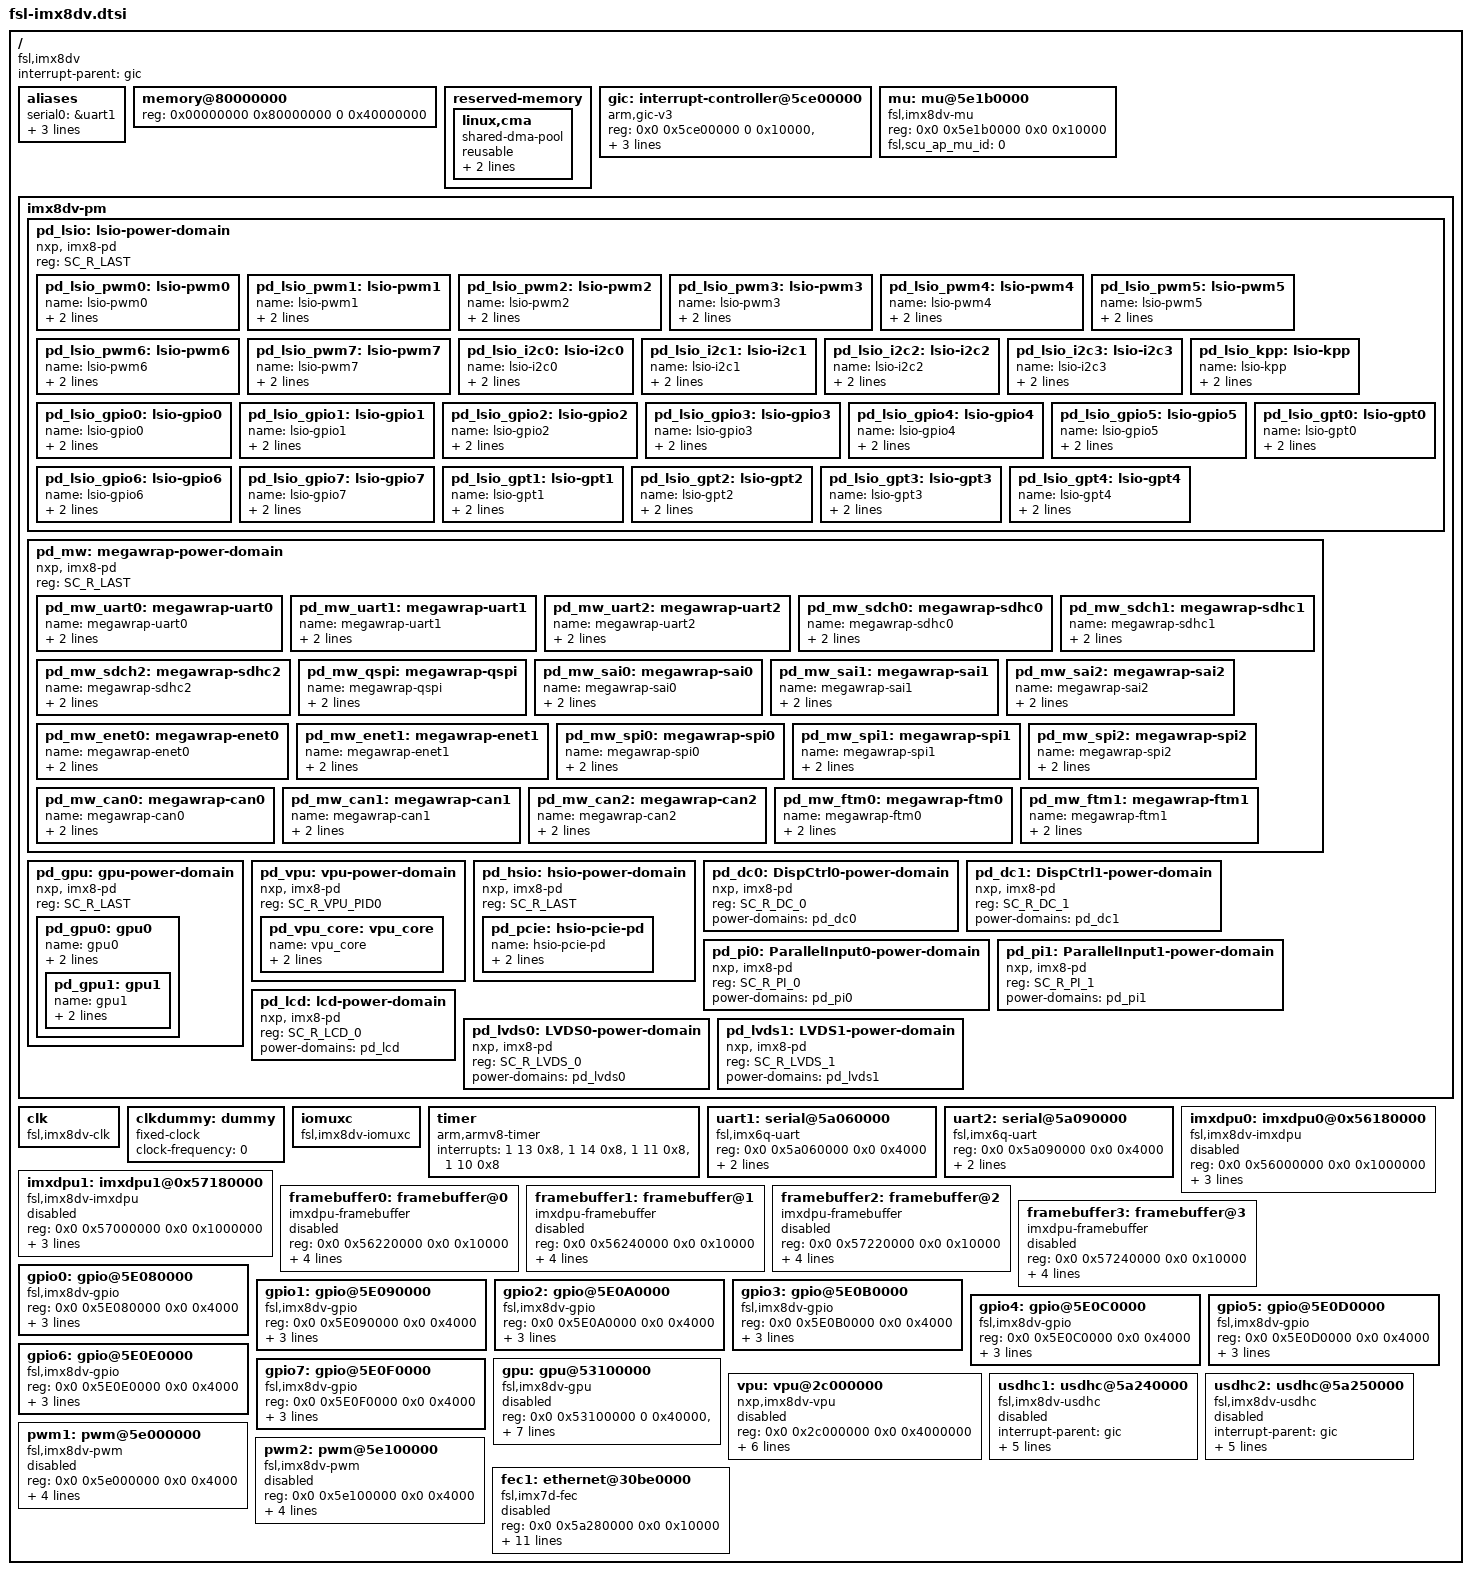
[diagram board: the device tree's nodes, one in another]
/*
 * Device Tree Include file for Freescale i.MX8 family SoC.
 *
 * Copyright (C) 2015, Freescale Semiconductor inc
 *
 * Nitin Garg <nitin.garg@freescale.com>
 *
 * This file is dual-licensed: you can use it either under the terms
 * of the GPLv2 or the X11 license, at your option. Note that this dual
 * licensing only applies to this file, and not this project as a
 * whole.
 *
 *  a) This library is free software; you can redistribute it and/or
 *     modify it under the terms of the GNU General Public License as
 *     published by the Free Software Foundation; either version 2 of the
 *     License, or (at your option) any later version.
 *
 *     This library is distributed in the hope that it will be useful,
 *     but WITHOUT ANY WARRANTY; without even the implied warranty of
 *     MERCHANTABILITY or FITNESS FOR A PARTICULAR PURPOSE.  See the
 *     GNU General Public License for more details.
 *
 *     You should have received a copy of the GNU General Public
 *     License along with this library; if not, write to the Free
 *     Software Foundation, Inc., 51 Franklin St, Fifth Floor, Boston,
 *     MA 02110-1301 USA
 *
 * Or, alternatively,
 *
 *  b) Permission is hereby granted, free of charge, to any person
 *     obtaining a copy of this software and associated documentation
 *     files (the "Software"), to deal in the Software without
 *     restriction, including without limitation the rights to use,
 *     copy, modify, merge, publish, distribute, sublicense, and/or
 *     sell copies of the Software, and to permit persons to whom the
 *     Software is furnished to do so, subject to the following
 *     conditions:
 *
 *     The above copyright notice and this permission notice shall be
 *     included in all copies or substantial portions of the Software.
 *
 *     THE SOFTWARE IS PROVIDED "AS IS", WITHOUT WARRANTY OF ANY KIND,
 *     EXPRESS OR IMPLIED, INCLUDING BUT NOT LIMITED TO THE WARRANTIES
 *     OF MERCHANTABILITY, FITNESS FOR A PARTICULAR PURPOSE AND
 *     NONINFRINGEMENT. IN NO EVENT SHALL THE AUTHORS OR COPYRIGHT
 *     HOLDERS BE LIABLE FOR ANY CLAIM, DAMAGES OR OTHER LIABILITY,
 *     WHETHER IN AN ACTION OF CONTRACT, TORT OR OTHERWISE, ARISING
 *     FROM, OUT OF OR IN CONNECTION WITH THE SOFTWARE OR THE USE OR
 *     OTHER DEALINGS IN THE SOFTWARE.
 */

#include "fsl-imx8dv-ca53.dtsi"
#include <dt-bindings/clock/imx8dv-clock.h>
#include <dt-bindings/soc/imx_rsrc.h>

/ {
	compatible = "fsl,imx8dv";
	interrupt-parent = <&gic>;
	#address-cells = <2>;
	#size-cells = <2>;

	aliases {
		serial0 = &uart1;
		serial1 = &uart2;
		mmc0 = &usdhc1;
        ethernet0 = &fec1;
	};

	memory@80000000 {
		device_type = "memory";
		reg = <0x00000000 0x80000000 0 0x40000000>;
		      /* DRAM space - 1, size : 1 GB DRAM */
	};

        reserved-memory {
		#address-cells = <2>;
                #size-cells = <2>;
                ranges;

                /* global autoconfigured region for contiguous allocations */
                linux,cma {
                        compatible = "shared-dma-pool";
                        reusable;
                        size = <0 0x08000000>;
                        linux,cma-default;
                };
        };

	gic: interrupt-controller@5ce00000 {
		compatible = "arm,gic-v3";
		reg = <0x0 0x5ce00000 0 0x10000>, /* GIC Dist */
		      <0x0 0x5cf00000 0 0xC0000>; /* GICR (RD_base + SGI_base) */
		#interrupt-cells = <3>;
		interrupt-controller;
		interrupts = <1 9 0x4>;
	};

	mu: mu@5e1b0000 {
		compatible = "fsl,imx8dv-mu","fsl,imx7d-mu", "fsl,imx6sx-mu";
		reg = <0x0 0x5e1b0000 0x0 0x10000>;
		fsl,scu_ap_mu_id = <0>;
		status = "okay";
	};

	imx8dv-pm {
		#address-cells = <1>;
		#size-cells = <0>;

		pd_lsio: lsio-power-domain {
			compatible = "nxp, imx8-pd";
			reg = <SC_R_LAST>;
			#power-domain-cells = <0>;
			#address-cells = <1>;
			#size-cells = <0>;
			pd_lsio_pwm0: lsio-pwm0 {
				name = "lsio-pwm0";
				reg = <SC_R_PWM_0>;
				#power-domain-cells = <0>;
				power-domains = <&pd_lsio>;
			};
			pd_lsio_pwm1: lsio-pwm1 {
				name = "lsio-pwm1";
				reg = <SC_R_PWM_1>;
				#power-domain-cells = <0>;
				power-domains = <&pd_lsio>;
			};
			pd_lsio_pwm2: lsio-pwm2 {
				name = "lsio-pwm2";
				reg = <SC_R_PWM_2>;
				#power-domain-cells = <0>;
				power-domains = <&pd_lsio>;
			};
			pd_lsio_pwm3: lsio-pwm3 {
				name = "lsio-pwm3";
				reg = <SC_R_PWM_3>;
				#power-domain-cells = <0>;
				power-domains = <&pd_lsio>;
			};
			pd_lsio_pwm4: lsio-pwm4 {
				name = "lsio-pwm4";
				reg = <SC_R_PWM_4>;
				#power-domain-cells = <0>;
				power-domains = <&pd_lsio>;
			};
			pd_lsio_pwm5: lsio-pwm5 {
				name = "lsio-pwm5";
				reg = <SC_R_PWM_5>;
				#power-domain-cells = <0>;
				power-domains = <&pd_lsio>;
			};
			pd_lsio_pwm6: lsio-pwm6 {
				name = "lsio-pwm6";
				reg = <SC_R_PWM_6>;
				#power-domain-cells = <0>;
				power-domains = <&pd_lsio>;
			};
			pd_lsio_pwm7: lsio-pwm7 {
				name = "lsio-pwm7";
				reg = <SC_R_PWM_7>;
				#power-domain-cells = <0>;
				power-domains = <&pd_lsio>;
			};
			pd_lsio_i2c0: lsio-i2c0 {
				name = "lsio-i2c0";
				reg = <SC_R_I2C_0>;
				#power-domain-cells = <0>;
				power-domains = <&pd_lsio>;
			};
			pd_lsio_i2c1: lsio-i2c1 {
				name = "lsio-i2c1";
				reg = <SC_R_I2C_1>;
				#power-domain-cells = <0>;
				power-domains = <&pd_lsio>;
			};
			pd_lsio_i2c2: lsio-i2c2 {
				name = "lsio-i2c2";
				reg = <SC_R_I2C_2>;
				#power-domain-cells = <0>;
				power-domains = <&pd_lsio>;
			};
			pd_lsio_i2c3: lsio-i2c3 {
				name = "lsio-i2c3";
				reg = <SC_R_I2C_3>;
				#power-domain-cells = <0>;
				power-domains = <&pd_lsio>;
			};
			pd_lsio_kpp: lsio-kpp {
				name = "lsio-kpp";
				reg = <SC_R_KPP>;
				#power-domain-cells = <0>;
				power-domains = <&pd_lsio>;
			};
			pd_lsio_gpio0: lsio-gpio0 {
				name = "lsio-gpio0";
				reg = <SC_R_GPIO_0>;
				#power-domain-cells = <0>;
				power-domains = <&pd_lsio>;
			};
			pd_lsio_gpio1: lsio-gpio1 {
				name = "lsio-gpio1";
				reg = <SC_R_GPIO_1>;
				#power-domain-cells = <0>;
				power-domains = <&pd_lsio>;
			};
			pd_lsio_gpio2: lsio-gpio2 {
				name = "lsio-gpio2";
				reg = <SC_R_GPIO_2>;
				#power-domain-cells = <0>;
				power-domains = <&pd_lsio>;
			};
			pd_lsio_gpio3: lsio-gpio3 {
				name = "lsio-gpio3";
				reg = <SC_R_GPIO_3>;
				#power-domain-cells = <0>;
				power-domains = <&pd_lsio>;
			};
			pd_lsio_gpio4: lsio-gpio4 {
				name = "lsio-gpio4";
				reg = <SC_R_GPIO_4>;
				#power-domain-cells = <0>;
				power-domains = <&pd_lsio>;
			};
			pd_lsio_gpio5: lsio-gpio5 {
				name = "lsio-gpio5";
				reg = <SC_R_GPIO_5>;
				#power-domain-cells = <0>;
				power-domains = <&pd_lsio>;
			};
			pd_lsio_gpio6: lsio-gpio6 {
				name = "lsio-gpio6";
				reg = <SC_R_GPIO_6>;
				#power-domain-cells = <0>;
				power-domains = <&pd_lsio>;
			};
			pd_lsio_gpio7: lsio-gpio7 {
				name = "lsio-gpio7";
				reg = <SC_R_GPIO_7>;
				#power-domain-cells = <0>;
				power-domains = <&pd_lsio>;
			};
			pd_lsio_gpt0: lsio-gpt0 {
				name = "lsio-gpt0";
				reg = <SC_R_GPT_0>;
				#power-domain-cells = <0>;
				power-domains = <&pd_lsio>;
			};
			pd_lsio_gpt1: lsio-gpt1 {
				name = "lsio-gpt1";
				reg = <SC_R_GPT_1>;
				#power-domain-cells = <0>;
				power-domains = <&pd_lsio>;
			};
			pd_lsio_gpt2: lsio-gpt2 {
				name = "lsio-gpt2";
				reg = <SC_R_GPT_2>;
				#power-domain-cells = <0>;
				power-domains = <&pd_lsio>;
			};
			pd_lsio_gpt3: lsio-gpt3 {
				name = "lsio-gpt3";
				reg = <SC_R_GPT_3>;
				#power-domain-cells = <0>;
				power-domains = <&pd_lsio>;
			};
			pd_lsio_gpt4: lsio-gpt4 {
				name = "lsio-gpt4";
				reg = <SC_R_GPT_4>;
				#power-domain-cells = <0>;
				power-domains = <&pd_lsio>;
			};
		};

		pd_mw: megawrap-power-domain {
			compatible = "nxp, imx8-pd";
			reg = <SC_R_LAST>;
			#power-domain-cells = <0>;
			#address-cells = <1>;
			#size-cells = <0>;
			pd_mw_uart0: megawrap-uart0 {
				name = "megawrap-uart0";
				reg = <SC_R_UART_0>;
				#power-domain-cells = <0>;
				power-domains = <&pd_mw>;
			};
			pd_mw_uart1: megawrap-uart1 {
				name = "megawrap-uart1";
				reg = <SC_R_UART_1>;
				#power-domain-cells = <0>;
				power-domains = <&pd_mw>;
			};
			pd_mw_uart2: megawrap-uart2 {
				name = "megawrap-uart2";
				reg = <SC_R_UART_2>;
				#power-domain-cells = <0>;
				power-domains = <&pd_mw>;
			};
			pd_mw_sdch0: megawrap-sdhc0 {
				name = "megawrap-sdhc0";
				reg = <SC_R_SDHC_0>;
				#power-domain-cells = <0>;
				power-domains = <&pd_mw>;
			};
			pd_mw_sdch1: megawrap-sdhc1 {
				name = "megawrap-sdhc1";
				reg = <SC_R_SDHC_1>;
				#power-domain-cells = <0>;
				power-domains = <&pd_mw>;
			};
			pd_mw_sdch2: megawrap-sdhc2 {
				name = "megawrap-sdhc2";
				reg = <SC_R_SDHC_2>;
				#power-domain-cells = <0>;
				power-domains = <&pd_mw>;
			};
			pd_mw_qspi: megawrap-qspi {
				name = "megawrap-qspi";
				reg = <SC_R_QSPI_0>;
				#power-domain-cells = <0>;
				power-domains = <&pd_mw>;
			};
			pd_mw_sai0: megawrap-sai0 {
				name = "megawrap-sai0";
				reg = <SC_R_SAI_0>;
				#power-domain-cells = <0>;
				power-domains = <&pd_mw>;
			};
			pd_mw_sai1: megawrap-sai1 {
				name = "megawrap-sai1";
				reg = <SC_R_SAI_1>;
				#power-domain-cells = <0>;
				power-domains = <&pd_mw>;
			};
			pd_mw_sai2: megawrap-sai2 {
				name = "megawrap-sai2";
				reg = <SC_R_SAI_2>;
				#power-domain-cells = <0>;
				power-domains = <&pd_mw>;
			};
			pd_mw_enet0: megawrap-enet0 {
				name = "megawrap-enet0";
				reg = <SC_R_ENET_0>;
				#power-domain-cells = <0>;
				power-domains = <&pd_mw>;
			};
			pd_mw_enet1: megawrap-enet1 {
				name = "megawrap-enet1";
				reg = <SC_R_ENET_1>;
				#power-domain-cells = <0>;
				power-domains = <&pd_mw>;
			};
			pd_mw_spi0: megawrap-spi0 {
				name = "megawrap-spi0";
				reg = <SC_R_SPI_0>;
				#power-domain-cells = <0>;
				power-domains = <&pd_mw>;
			};
			pd_mw_spi1: megawrap-spi1 {
				name = "megawrap-spi1";
				reg = <SC_R_SPI_1>;
				#power-domain-cells = <0>;
				power-domains = <&pd_mw>;
			};
			pd_mw_spi2: megawrap-spi2 {
				name = "megawrap-spi2";
				reg = <SC_R_SPI_2>;
				#power-domain-cells = <0>;
				power-domains = <&pd_mw>;
			};
			pd_mw_can0: megawrap-can0 {
				name = "megawrap-can0";
				reg = <SC_R_CAN_0>;
				#power-domain-cells = <0>;
				power-domains = <&pd_mw>;
			};
			pd_mw_can1: megawrap-can1 {
				name = "megawrap-can1";
				reg = <SC_R_CAN_1>;
				#power-domain-cells = <0>;
				power-domains = <&pd_mw>;
			};
			pd_mw_can2: megawrap-can2 {
				name = "megawrap-can2";
				reg = <SC_R_CAN_2>;
				#power-domain-cells = <0>;
				power-domains = <&pd_mw>;
			};
			pd_mw_ftm0: megawrap-ftm0 {
				name = "megawrap-ftm0";
				reg = <SC_R_FTM_0>;
				#power-domain-cells = <0>;
				power-domains = <&pd_mw>;
			};
			pd_mw_ftm1: megawrap-ftm1 {
				name = "megawrap-ftm1";
				reg = <SC_R_FTM_1>;
				#power-domain-cells = <0>;
				power-domains = <&pd_mw>;
			};
		};

		pd_gpu: gpu-power-domain {
			compatible = "nxp, imx8-pd";
			reg = <SC_R_LAST>;
			#power-domain-cells = <0>;
			#address-cells = <1>;
			#size-cells = <0>;

			pd_gpu0: gpu0 {
				name = "gpu0";
				reg = <SC_R_GPU_0_PID0>;
				#power-domain-cells = <0>;
				power-domains =<&pd_gpu>;
				#address-cells = <1>;
				#size-cells = <0>;

				pd_gpu1: gpu1 {
					name = "gpu1";
					reg = <SC_R_GPU_1_PID0>;
					#power-domain-cells = <0>;
					power-domains =<&pd_gpu0>;
				};
			};
		};

		pd_vpu: vpu-power-domain {
			compatible = "nxp, imx8-pd";
			reg = <SC_R_VPU_PID0>;
			#power-domain-cells = <0>;
			#address-cells = <1>;
			#size-cells = <0>;

			pd_vpu_core: vpu_core {
				name = "vpu_core";
				reg = <SC_R_VPUCORE>;
				#power-domain-cells = <0>;
				power-domains =<&pd_vpu>;
			};
		};

		pd_hsio: hsio-power-domain {
			compatible = "nxp, imx8-pd";
			reg = <SC_R_LAST>;
			#power-domain-cells = <0>;
			#address-cells = <1>;
			#size-cells = <0>;

			pd_pcie: hsio-pcie-pd {
				name = "hsio-pcie-pd";
				reg = <SC_R_PCIE_A>;
				#power-domain-cells = <0>;
				power-domains =<&pd_hsio>;
			};
		};
		pd_dc0: DispCtrl0-power-domain {
			compatible = "nxp, imx8-pd";
			reg = <SC_R_DC_0>;
			#power-domain-cells = <0>;
			power-domains =<&pd_dc0>;
		};
		pd_dc1: DispCtrl1-power-domain {
			compatible = "nxp, imx8-pd";
			reg = <SC_R_DC_1>;
			#power-domain-cells = <0>;
			power-domains =<&pd_dc1>;
		};
		pd_pi0: ParallelInput0-power-domain {
			compatible = "nxp, imx8-pd";
			reg = <SC_R_PI_0>;
			#power-domain-cells = <0>;
			power-domains =<&pd_pi0>;
		};
		pd_pi1: ParallelInput1-power-domain {
			compatible = "nxp, imx8-pd";
			reg = <SC_R_PI_1>;
			#power-domain-cells = <0>;
			power-domains =<&pd_pi1>;
		};
		pd_lcd: lcd-power-domain {
			compatible = "nxp, imx8-pd";
			reg = <SC_R_LCD_0>;
			#power-domain-cells = <0>;
			power-domains =<&pd_lcd>;
		};
		pd_lvds0: LVDS0-power-domain {
			compatible = "nxp, imx8-pd";
			reg = <SC_R_LVDS_0>;
			#power-domain-cells = <0>;
			power-domains =<&pd_lvds0>;
		};
		pd_lvds1: LVDS1-power-domain {
			compatible = "nxp, imx8-pd";
			reg = <SC_R_LVDS_1>;
			#power-domain-cells = <0>;
			power-domains =<&pd_lvds1>;
		};
	};

	clk: clk {
		compatible = "fsl,imx8dv-clk";
		#clock-cells = <1>;
	};

    clkdummy: dummy {
        #clock-cells = <0>;
        compatible = "fixed-clock";
        clock-frequency = <0>;
    };

    iomuxc: iomuxc {
		compatible = "fsl,imx8dv-iomuxc";
	};

	timer {
		compatible = "arm,armv8-timer";
		interrupts = <1 13 0x8>, /* Physical Secure PPI, active-low */
			     <1 14 0x8>, /* Physical Non-Secure PPI, active-low */
			     <1 11 0x8>, /* Virtual PPI, active-low */
			     <1 10 0x8>; /* Hypervisor PPI, active-low */
	};

	uart1: serial@5a060000 {
		compatible = "fsl,imx6q-uart", "fsl,imx21-uart";
		reg = <0x0 0x5a060000 0x0 0x4000>;
		interrupts = <0 219 4>;
		power-domains = <&pd_mw_uart0>;
	};

	uart2: serial@5a090000 {
		compatible = "fsl,imx6q-uart", "fsl,imx21-uart";
		reg = <0x0 0x5a090000 0x0 0x4000>;
		interrupts = <0 220 4>;
		power-domains = <&pd_mw_uart1>;
	};

	imxdpu0:  imxdpu0@0x56180000 {
		compatible = "fsl,imx8dv-imxdpu";
		reg = <0x0 0x56000000 0x0 0x1000000>;
		interrupts = 	<0 40 0x4>, <0 41 0x4>, <0 42 0x4>, <0 43 0x4>,
				<0 44 0x4>, <0 45 0x4>, <0 46 0x4>, <0 47 0x4>,
				<0 48 0x4>, <0 49 0x4>, <0 50 0x4>;
		interrupt-names = 	"irq_grp00", "irq_grp01", "irq_grp02", "irq_grp03",
					"irq_grp04", "irq_grp05", "irq_grp06", "irq_grp07",
					"irq_grp08", "irq_grp09", "irq_grp10";

		status = "disabled";
	};

	imxdpu1:  imxdpu1@0x57180000 {
		compatible = "fsl,imx8dv-imxdpu";
		reg = <0x0 0x57000000 0x0 0x1000000>;
		interrupts = 	<0 152 0x4>, <0 151 0x4>, <0 153 0x4>, <0 154 0x4>,
				<0 155 0x4>, <0 156 0x4>, <0 157 0x4>, <0 158 0x4>,
				<0 159 0x4>, <0 160 0x4>, <0 161 0x4>;
		interrupt-names = 	"irq_grp00", "irq_grp01", "irq_grp02", "irq_grp03",
					"irq_grp04", "irq_grp05", "irq_grp06", "irq_grp07",
					"irq_grp08", "irq_grp09", "irq_grp10";
		status = "disabled";
	};

	framebuffer0: framebuffer@0 {
		compatible = "imxdpu-framebuffer";
		reg = <0x0 0x56220000 0x0 0x10000>;
		width = <640>;
		height = <480>;
		stride = <(640*4)>;
		format = "b8g8r8a8";
		status = "disabled";
	};

	framebuffer1: framebuffer@1 {
		compatible = "imxdpu-framebuffer";
		reg = <0x0 0x56240000 0x0 0x10000>;
		width = <640>;
		height = <480>;
		stride = <(640 * 4)>;
		format = "ayuv";
		status = "disabled";
	};

	framebuffer2: framebuffer@2 {
		compatible = "imxdpu-framebuffer";
		reg = <0x0 0x57220000 0x0 0x10000>;
		width = <640>;
		height = <480>;
		stride = <(640 * 4)>;
		format = "nv12";
		status = "disabled";
	};

	framebuffer3: framebuffer@3 {
		compatible = "imxdpu-framebuffer";
		reg = <0x0 0x57240000 0x0 0x10000>;
		width = <640>;
		height = <480>;
		stride = <640>;
		format = "nv12";
		status = "disabled";
	};

	gpio0: gpio@5E080000 {
		compatible = "fsl,imx8dv-gpio", "fsl,imx35-gpio";
		reg = <0x0 0x5E080000 0x0 0x4000>;
		interrupts = <0 168 4>;
		gpio-controller;
		#gpio-cells = <2>;
		interrupt-controller;
		#interrupt-cells = <2>;
	};

	gpio1: gpio@5E090000 {
		compatible = "fsl,imx8dv-gpio", "fsl,imx35-gpio";
		reg = <0x0 0x5E090000 0x0 0x4000>;
		interrupts = <0 169 4>;
		gpio-controller;
		#gpio-cells = <2>;
		interrupt-controller;
		#interrupt-cells = <2>;
	};

	gpio2: gpio@5E0A0000 {
		compatible = "fsl,imx8dv-gpio", "fsl,imx35-gpio";
		reg = <0x0 0x5E0A0000 0x0 0x4000>;
		interrupts = <0 170 4>;
		gpio-controller;
		#gpio-cells = <2>;
		interrupt-controller;
		#interrupt-cells = <2>;
	};

	gpio3: gpio@5E0B0000 {
		compatible = "fsl,imx8dv-gpio", "fsl,imx35-gpio";
		reg = <0x0 0x5E0B0000 0x0 0x4000>;
		interrupts = <0 171 4>;
		gpio-controller;
		#gpio-cells = <2>;
		interrupt-controller;
		#interrupt-cells = <2>;
	};

	gpio4: gpio@5E0C0000 {
		compatible = "fsl,imx8dv-gpio", "fsl,imx35-gpio";
		reg = <0x0 0x5E0C0000 0x0 0x4000>;
		interrupts = <0 172 4>;
		gpio-controller;
		#gpio-cells = <2>;
		interrupt-controller;
		#interrupt-cells = <2>;
	};

	gpio5: gpio@5E0D0000 {
		compatible = "fsl,imx8dv-gpio", "fsl,imx35-gpio";
		reg = <0x0 0x5E0D0000 0x0 0x4000>;
		interrupts = <0 173 4>;
		gpio-controller;
		#gpio-cells = <2>;
		interrupt-controller;
		#interrupt-cells = <2>;
	};

	gpio6: gpio@5E0E0000 {
		compatible = "fsl,imx8dv-gpio", "fsl,imx35-gpio";
		reg = <0x0 0x5E0E0000 0x0 0x4000>;
		interrupts = <0 174 4>;
		gpio-controller;
		#gpio-cells = <2>;
		interrupt-controller;
		#interrupt-cells = <2>;
	};

	gpio7: gpio@5E0F0000 {
		compatible = "fsl,imx8dv-gpio", "fsl,imx35-gpio";
		reg = <0x0 0x5E0F0000 0x0 0x4000>;
		interrupts = <0 171 4>;
		gpio-controller;
		#gpio-cells = <2>;
		interrupt-controller;
		#interrupt-cells = <2>;
	};

	gpu: gpu@53100000 {
		compatible = "fsl,imx8dv-gpu", "fsl,imx8x-gpu";
		reg = <0x0 0x53100000 0 0x40000>, <0x0 0x54100000 0x0 0x40000>, <0x0 0x0 0x0 0x0>, <0x0 0x0 0x0 0x01000000>;
		reg-names = "iobase_3d_0","iobase_3d_1", "phys_baseaddr", "contiguous_mem";
		interrupts = <0 64 0x4>, <0 65 0x4>;
		interrupt-names = "irq_3d_0", "irq_3d_1";
		clocks = <&clk IMX8DV_GPU0_CORE_CLK>, <&clk IMX8DV_GPU0_SHADER_CLK>,
						<&clk IMX8DV_GPU1_CORE_CLK>, <&clk IMX8DV_GPU1_SHADER_CLK>;
		clock-names = "clk_core_3d_0", "clk_shader_3d_0", "clk_core_3d_1", "clk_shader_3d_1";
		status = "disabled";
	};

	vpu: vpu@2c000000 {
		compatible = "nxp,imx8dv-vpu", "nxp,imx8x-vpu";
		reg = <0x0 0x2c000000 0x0 0x4000000>;
		reg-names = "iobase_vpu";
		interrupts = <0 169 0x4>;
		interrupt-names = "irq_vpu";
		clocks = <&clk IMX8DV_VPU_DDR_CLK>, <&clk IMX8DV_VPU_CABAC_CLK>,<&clk IMX8DV_VPU_XUVI_CLK>, <&clk IMX8DV_VPU_UART_CLK>;
		clock-names = "clk_vpu_ddr", "clk_vpu_cabac","clk_vpu_xuvi", "clk_vpu_uart";
		status = "disabled";
		power-domains = <&pd_vpu_core>;
	};

	usdhc1: usdhc@5a240000 {
		compatible = "fsl,imx8dv-usdhc", "fsl,imx6sl-usdhc";
		status = "disabled";
		interrupt-parent = <&gic>;
		interrupts = <0 225 4>;
		reg = <0x0 0x5a240000 0x0 0x10000>;
		clocks = <&clk IMX8DV_SDHC_BUS_CLK>, <&clk IMX8DV_SDHC0_CLK>, <&clkdummy>;
		clock-names = "ipg", "per", "ahb";
		power-domains = <&pd_mw_sdch0>;
	};

	usdhc2: usdhc@5a250000 {
		compatible = "fsl,imx8dv-usdhc", "fsl,imx6sl-usdhc";
		status = "disabled";
		interrupt-parent = <&gic>;
		interrupts = <0 226 4>;
		reg = <0x0 0x5a250000 0x0 0x10000>;
		clocks = <&clk IMX8DV_SDHC_BUS_CLK>, <&clk IMX8DV_SDHC1_CLK>, <&clkdummy>;
		clock-names = "ipg", "per", "ahb";
		power-domains = <&pd_mw_sdch1>;
	};

	pwm1: pwm@5e000000 {
		#pwm-cells = <2>;
		compatible = "fsl,imx8dv-pwm", "fsl,imx27-pwm";
		reg = <0x0 0x5e000000 0x0 0x4000>;
		interrupts = <0 94 4>;
		clocks = <&clk IMX8DV_PWM0_CLK>,
			 <&clk IMX8DV_PWM0_CLK>;
		clock-names = "ipg", "per";
		status = "disabled";
		power-domains = <&pd_lsio_pwm0>;
	};

	pwm2: pwm@5e100000 {
		#pwm-cells = <2>;
		compatible = "fsl,imx8dv-pwm", "fsl,imx27-pwm";
		reg = <0x0 0x5e100000 0x0 0x4000>;
		interrupts = <0 95 4>;
		clocks = <&clk IMX8DV_PWM0_CLK>,
			 <&clk IMX8DV_PWM0_CLK>;
		clock-names = "ipg", "per";
		status = "disabled";
		power-domains = <&pd_lsio_pwm1>;
	};

	fec1: ethernet@30be0000 {
		compatible = "fsl,imx7d-fec", "fsl,imx6sx-fec";
		reg = <0x0 0x5a280000 0x0 0x10000>;
		interrupts = <0 212 4>;
		clocks = <&clk IMX8DV_ENET_BUS_CLK>, <&clk IMX8DV_ANATOP_CLK>,
			<&clk IMX8DV_ENET0_CLK>, <&clk IMX8DV_ENET0_TIME_CLK>;
		clock-names = "ipg", "ahb",
                "enet_clk_ref", "ptp";
        assigned-clocks = <&clk IMX8DV_ENET0_CLK>, <&clk IMX8DV_ENET0_TIME_CLK>;
		assigned-clock-rates = <125000000>, <25000000>;
		fsl,num-tx-queues=<3>;
		fsl,num-rx-queues=<3>;
		fsl,wakeup_irq = <0>;
		status = "disabled";
		power-domains = <&pd_mw_enet0>;
	};

};
